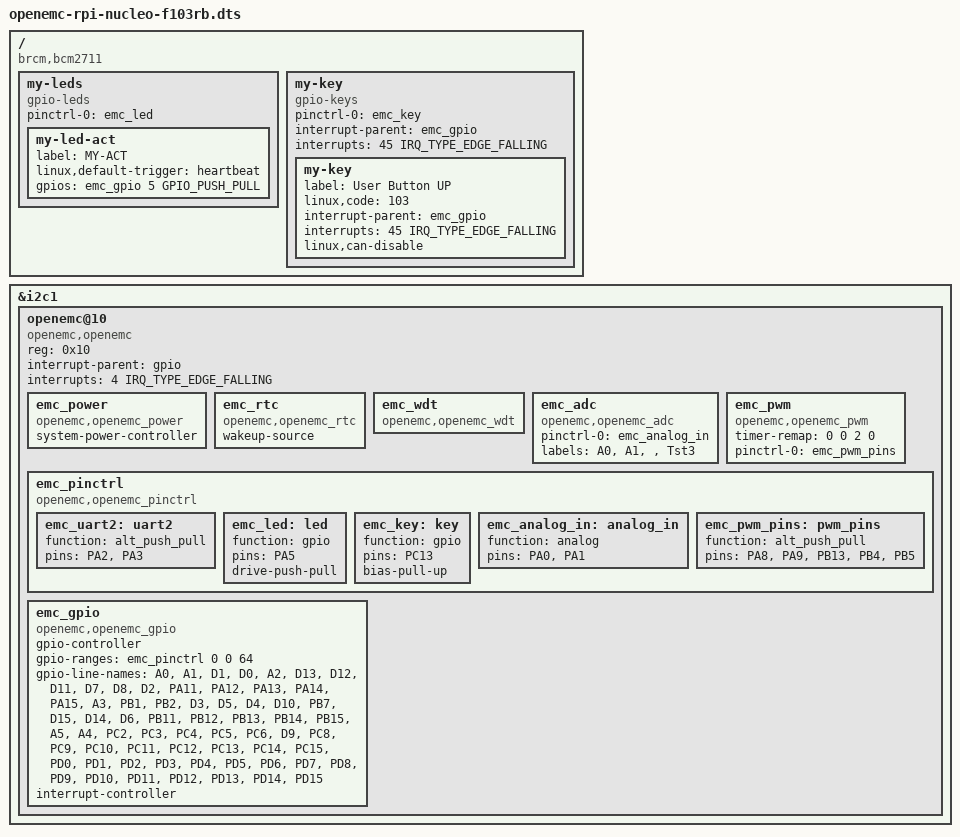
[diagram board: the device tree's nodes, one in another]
/* Example device tree overlay for connecting OpenEMC
   on a STM Nucleo-F103RB board to a Raspberry Pi 4 via
   I2C bus 1 and IRQ line at GPIO 4.

   The LED on the board is configured to show the Linux hearbeat.
   The key is exposed as an input device.
*/

#include <dt-bindings/interrupt-controller/irq.h>
#include <dt-bindings/gpio/gpio.h>

/dts-v1/;
/plugin/;

/ {
    compatible = "brcm,bcm2711";

    fragment@0 {
        target = <&i2c1>;

        __overlay__ {
            #address-cells = <1>;
            #size-cells = <0>;

            openemc@10 {
                compatible = "openemc,openemc";
                reg = <0x10>;

                interrupt-parent = <&gpio>;
                interrupts = <4 IRQ_TYPE_EDGE_FALLING>;

                emc_power: emc_power {
                    compatible = "openemc,openemc_power";
                    system-power-controller;
                };

                emc_rtc: emc_rtc {
                    compatible = "openemc,openemc_rtc";
                    wakeup-source;
                };

                emc_wdt: emc_wdt {
                    compatible = "openemc,openemc_wdt";
                };

                emc_adc: emc_adc {
                    compatible = "openemc,openemc_adc";

                    pinctrl-names = "default";
                    pinctrl-0 = <&emc_analog_in>;

                    labels = "A0", "A1", "", "Tst3";
                };

                emc_pwm: emc_pwm {
                    compatible = "openemc,openemc_pwm";
                    #pwm-cells = <3>;

                    timer-remap = <0 0 2 0>;

                    pinctrl-names = "default";
                    pinctrl-0 = <&emc_pwm_pins>;
                };

                emc_pinctrl: emc_pinctrl {
                    compatible = "openemc,openemc_pinctrl";

                    emc_uart2: uart2 {
                        function = "alt_push_pull";
                        pins = "PA2", "PA3";
                    };

                    emc_led: led {
                        function = "gpio";
                        pins = "PA5";
                        drive-push-pull;
                    };

                    emc_key: key {
                        function = "gpio";
                        pins = "PC13";
                        bias-pull-up;
                    };

                    emc_analog_in: analog_in {
                        function = "analog";
                        pins = "PA0", "PA1";
                    };

                    emc_pwm_pins: pwm_pins {
                        function = "alt_push_pull";
                        pins = "PA8", "PA9", "PB13", "PB4", "PB5";
                    };
                };

                emc_gpio: emc_gpio {
                    compatible = "openemc,openemc_gpio";

                    gpio-controller;
                    #gpio-cells = <2>;
                    gpio-ranges = <&emc_pinctrl 0 0 64>;
                    gpio-line-names =
                        "A0", "A1", "D1", "D0", "A2", "D13", "D12", "D11",
                        "D7", "D8", "D2", "PA11", "PA12", "PA13", "PA14", "PA15",
                        "A3", "PB1", "PB2", "D3", "D5", "D4", "D10", "PB7",
                        "D15", "D14", "D6", "PB11", "PB12", "PB13", "PB14", "PB15",
                        "A5", "A4", "PC2", "PC3", "PC4", "PC5", "PC6", "D9",
                        "PC8", "PC9", "PC10", "PC11", "PC12", "PC13", "PC14", "PC15",
                        "PD0", "PD1", "PD2", "PD3", "PD4", "PD5", "PD6", "PD7",
                        "PD8", "PD9", "PD10", "PD11", "PD12", "PD13", "PD14", "PD15";

                    interrupt-controller;
                    #interrupt-cells = <2>;
                    #address-cells = <1>;
                };
            };
        };
    };

    fragment@1 {
        target-path = "/";

        __overlay__ {
            my-leds {
                compatible = "gpio-leds";

                pinctrl-names = "default";
                pinctrl-0 = <&emc_led>;

                my-led-act {
                    label = "MY-ACT";
                    linux,default-trigger = "heartbeat";
                    gpios = <&emc_gpio 5 GPIO_PUSH_PULL>;
                };
            };
        };
    };

    fragment@2 {
        target-path = "/";

        __overlay__ {
            my-key {
                compatible = "gpio-keys";

                pinctrl-names = "default";
                pinctrl-0 = <&emc_key>;

                interrupt-parent = <&emc_gpio>;
                interrupts = <45 IRQ_TYPE_EDGE_FALLING>;

                my-key {
                    label = "User Button UP";
                    linux,code = <103>;

                    //gpios = <&emc_gpio 45 GPIO_PULL_UP>;

                    interrupt-parent = <&emc_gpio>;
                    interrupts = <45 IRQ_TYPE_EDGE_FALLING>;
                    linux,can-disable;
                };
            };
        };
    };
};
